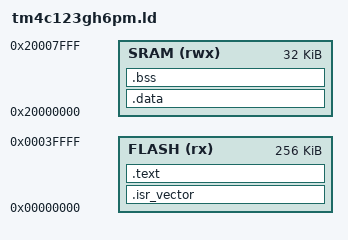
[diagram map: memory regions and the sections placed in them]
MEMORY
{
    FLASH (rx)  : ORIGIN = 0x00000000, LENGTH = 256K
    SRAM  (rwx) : ORIGIN = 0x20000000, LENGTH = 32K
}

_estack = ORIGIN(SRAM) + LENGTH(SRAM);

SECTIONS
{
    .isr_vector :
    {
        KEEP(*(.isr_vector))
    } > FLASH

    .text :
    {
        *(.text*)
        *(.rodata*)
        *(.ARM.exidx*)
        *(.eh_frame*)
        KEEP(*(.init))
        KEEP(*(.fini))
        _etext = .;
    } > FLASH

    .data : AT(_etext)
    {
        _data = .;
        *(.data*)
        _edata = .;
    } > SRAM

    .bss :
    {
        _bss = .;
        *(.bss*)
        *(COMMON)
        _ebss = .;
    } > SRAM
}
